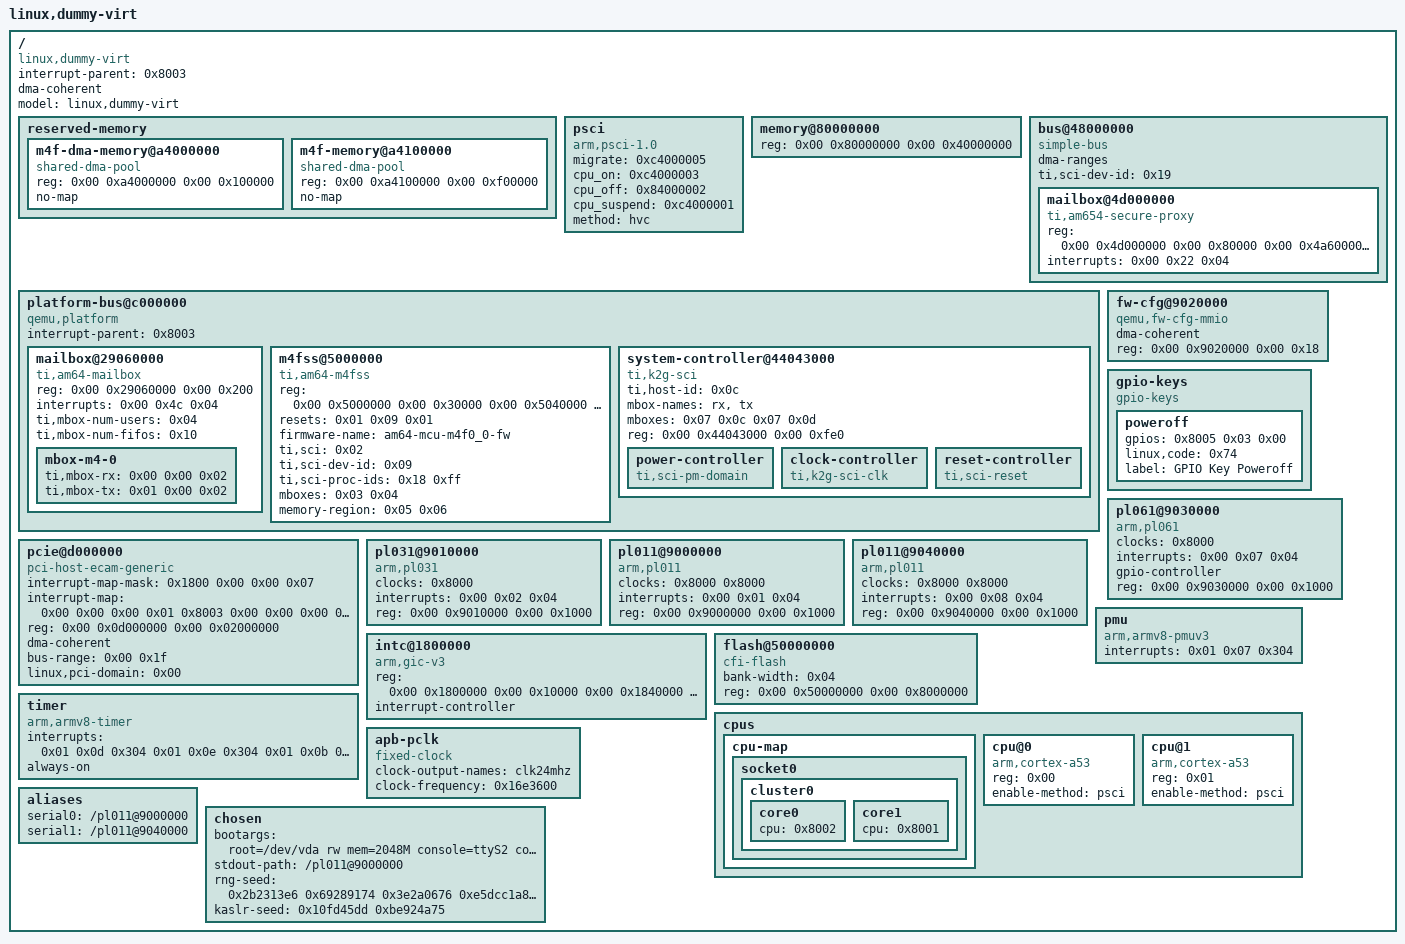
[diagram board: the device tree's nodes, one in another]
// SPDX-License-Identifier: GPL-2.0-or-later
/*
 * Copyright (c) 2026 CMBLU Energy AG
 * Author: Wadim Mueller <wafgo01@gmail.com>
 */
/dts-v1/;

/ {
	interrupt-parent = <0x8003>;
	dma-coherent;
	model = "linux,dummy-virt";
	#size-cells = <0x02>;
	#address-cells = <0x02>;
	compatible = "linux,dummy-virt";

	reserved-memory {
		#address-cells = <0x02>;
		#size-cells = <0x02>;
		ranges;

		m4f-dma-memory@a4000000 {
			compatible = "shared-dma-pool";
			reg = <0x00 0xa4000000 0x00 0x100000>;
			no-map;
			phandle = <0x05>;
		};

		m4f-memory@a4100000 {
			compatible = "shared-dma-pool";
			reg = <0x00 0xa4100000 0x00 0xf00000>;
			no-map;
			phandle = <0x06>;
		};
	};

	psci {
		migrate = <0xc4000005>;
		cpu_on = <0xc4000003>;
		cpu_off = <0x84000002>;
		cpu_suspend = <0xc4000001>;
		method = "hvc";
		compatible = "arm,psci-1.0", "arm,psci-0.2", "arm,psci";
	};

	memory@80000000 {
		reg = <0x00 0x80000000 0x00 0x40000000>;
		device_type = "memory";
	};

	bus@48000000 {
		bootph-all;
		compatible = "simple-bus";
		#address-cells = <0x02>;
		#size-cells = <0x02>;
		dma-ranges;
		ranges = <0x00 0x48000000 0x00 0x48000000 0x00 0x6400000>;
		ti,sci-dev-id = <0x19>;

		mailbox@4d000000 {
			bootph-all;
			compatible = "ti,am654-secure-proxy";
			#mbox-cells = <0x01>;
			reg-names = "target_data", "rt", "scfg";
			reg = <0x00 0x4d000000 0x00 0x80000 0x00 0x4a600000 0x00 0x80000 0x00 0x4a400000 0x00 0x80000>;
			interrupt-names = "rx_012";
			interrupts = <0x00 0x22 0x04>;
			phandle = <0x07>;
		};
	};

	platform-bus@c000000 {
		interrupt-parent = <0x8003>;
		ranges;
		#address-cells = <0x02>;
		#size-cells = <0x02>;
		compatible = "qemu,platform", "simple-bus";

		mailbox@29060000 {
			compatible = "ti,am64-mailbox";
			reg = <0x00 0x29060000 0x00 0x200>;
			interrupts = <0x00 0x4c 0x04>;
			#mbox-cells = <0x01>;
			ti,mbox-num-users = <0x04>;
			ti,mbox-num-fifos = <0x10>;
			status = "okay";
			phandle = <0x03>;

			mbox-m4-0 {
				ti,mbox-rx = <0x00 0x00 0x02>;
				ti,mbox-tx = <0x01 0x00 0x02>;
				phandle = <0x04>;
			};
		};

		m4fss@5000000 {
			compatible = "ti,am64-m4fss";
			reg = <0x00 0x5000000 0x00 0x30000 0x00 0x5040000 0x00 0x10000>;
			reg-names = "iram", "dram";
			resets = <0x01 0x09 0x01>;
			firmware-name = "am64-mcu-m4f0_0-fw";
			ti,sci = <0x02>;
			ti,sci-dev-id = <0x09>;
			ti,sci-proc-ids = <0x18 0xff>;
			mboxes = <0x03 0x04>;
			memory-region = <0x05 0x06>;
			status = "okay";
		};

		system-controller@44043000 {
			bootph-all;
			compatible = "ti,k2g-sci";
			ti,host-id = <0x0c>;
			mbox-names = "rx", "tx";
			mboxes = <0x07 0x0c 0x07 0x0d>;
			reg-names = "debug_messages";
			reg = <0x00 0x44043000 0x00 0xfe0>;
			phandle = <0x02>;

			power-controller {
				bootph-all;
				compatible = "ti,sci-pm-domain";
				#power-domain-cells = <0x02>;
			};

			clock-controller {
				bootph-all;
				compatible = "ti,k2g-sci-clk";
				#clock-cells = <0x02>;
			};

			reset-controller {
				bootph-all;
				compatible = "ti,sci-reset";
				#reset-cells = <0x02>;
				phandle = <0x01>;
			};
		};
	};

	fw-cfg@9020000 {
		dma-coherent;
		reg = <0x00 0x9020000 0x00 0x18>;
		compatible = "qemu,fw-cfg-mmio";
	};

	gpio-keys {
		compatible = "gpio-keys";

		poweroff {
			gpios = <0x8005 0x03 0x00>;
			linux,code = <0x74>;
			label = "GPIO Key Poweroff";
		};
	};

	pl061@9030000 {
		phandle = <0x8005>;
		clock-names = "apb_pclk";
		clocks = <0x8000>;
		interrupts = <0x00 0x07 0x04>;
		gpio-controller;
		#gpio-cells = <0x02>;
		compatible = "arm,pl061", "arm,primecell";
		reg = <0x00 0x9030000 0x00 0x1000>;
	};

	pcie@d000000 {
		interrupt-map-mask = <0x1800 0x00 0x00 0x07>;
		interrupt-map = <0x00 0x00 0x00 0x01 0x8003 0x00 0x00 0x00 0x03 0x04 0x00 0x00 0x00 0x02 0x8003 0x00 0x00 0x00 0x04 0x04 0x00 0x00 0x00 0x03 0x8003 0x00 0x00 0x00 0x05 0x04 0x00 0x00 0x00 0x04 0x8003 0x00 0x00 0x00 0x06 0x04 0x800 0x00 0x00 0x01 0x8003 0x00 0x00 0x00 0x04 0x04 0x800 0x00 0x00 0x02 0x8003 0x00 0x00 0x00 0x05 0x04 0x800 0x00 0x00 0x03 0x8003 0x00 0x00 0x00 0x06 0x04 0x800 0x00 0x00 0x04 0x8003 0x00 0x00 0x00 0x03 0x04 0x1000 0x00 0x00 0x01 0x8003 0x00 0x00 0x00 0x05 0x04 0x1000 0x00 0x00 0x02 0x8003 0x00 0x00 0x00 0x06 0x04 0x1000 0x00 0x00 0x03 0x8003 0x00 0x00 0x00 0x03 0x04 0x1000 0x00 0x00 0x04 0x8003 0x00 0x00 0x00 0x04 0x04 0x1800 0x00 0x00 0x01 0x8003 0x00 0x00 0x00 0x06 0x04 0x1800 0x00 0x00 0x02 0x8003 0x00 0x00 0x00 0x03 0x04 0x1800 0x00 0x00 0x03 0x8003 0x00 0x00 0x00 0x04 0x04 0x1800 0x00 0x00 0x04 0x8003 0x00 0x00 0x00 0x05 0x04>;
		#interrupt-cells = <0x01>;
		ranges = <0x1000000 0x00 0x00 0x00 0x3eff0000 0x00 0x10000 0x2000000 0x00 0x68000000 0x00 0x68000000 0x00 0x08000000>;
		reg = <0x00 0x0d000000 0x00 0x02000000>;
		dma-coherent;
		bus-range = <0x00 0x1f>;
		linux,pci-domain = <0x00>;
		#size-cells = <0x02>;
		#address-cells = <0x03>;
		device_type = "pci";
		compatible = "pci-host-ecam-generic";
	};

	pl031@9010000 {
		clock-names = "apb_pclk";
		clocks = <0x8000>;
		interrupts = <0x00 0x02 0x04>;
		reg = <0x00 0x9010000 0x00 0x1000>;
		compatible = "arm,pl031", "arm,primecell";
	};

	pl011@9000000 {
		clock-names = "uartclk", "apb_pclk";
		clocks = <0x8000 0x8000>;
		interrupts = <0x00 0x01 0x04>;
		reg = <0x00 0x9000000 0x00 0x1000>;
		compatible = "arm,pl011", "arm,primecell";
	};

	pl011@9040000 {
		clock-names = "uartclk", "apb_pclk";
		clocks = <0x8000 0x8000>;
		interrupts = <0x00 0x08 0x04>;
		reg = <0x00 0x9040000 0x00 0x1000>;
		compatible = "arm,pl011", "arm,primecell";
	};

	pmu {
		interrupts = <0x01 0x07 0x304>;
		compatible = "arm,armv8-pmuv3";
	};

	intc@1800000 {
		phandle = <0x8003>;
		reg = <0x00 0x1800000 0x00 0x10000
		       0x00 0x1840000 0x00 0x40000>;
		compatible = "arm,gic-v3";
		ranges;
		#size-cells = <0x02>;
		#address-cells = <0x02>;
		interrupt-controller;
		#interrupt-cells = <0x03>;
	};


	flash@50000000 {
		bank-width = <0x04>;
		reg = <0x00 0x50000000 0x00 0x8000000>;
		compatible = "cfi-flash";
	};
	cpus {
		#size-cells = <0x00>;
		#address-cells = <0x01>;

		cpu-map {

			socket0 {

				cluster0 {

					core0 {
						cpu = <0x8002>;
					};

					core1 {
						cpu = <0x8001>;
					};
				};
			};
		};

		cpu@0 {
			phandle = <0x8002>;
			reg = <0x00>;
			enable-method = "psci";
			compatible = "arm,cortex-a53";
			device_type = "cpu";
		};

		cpu@1 {
			phandle = <0x8001>;
			reg = <0x01>;
			enable-method = "psci";
			compatible = "arm,cortex-a53";
			device_type = "cpu";
		};
	};

	timer {
		interrupts = <0x01 0x0d 0x304 0x01 0x0e 0x304 0x01 0x0b 0x304 0x01 0x0a 0x304>;
		always-on;
		compatible = "arm,armv8-timer", "arm,armv7-timer";
	};

	apb-pclk {
		phandle = <0x8000>;
		clock-output-names = "clk24mhz";
		clock-frequency = <0x16e3600>;
		#clock-cells = <0x00>;
		compatible = "fixed-clock";
	};

	aliases {
		serial0 = "/pl011@9000000";
		serial1 = "/pl011@9040000";
	};

	chosen {
		bootargs = "root=/dev/vda rw  mem=2048M console=ttyS2 console=ttyAMA0 swiotlb=0 audit=0";
		stdout-path = "/pl011@9000000";
		rng-seed = <0x2b2313e6 0x69289174 0x3e2a0676 0xe5dcc1a8 0xc1e04c16 0x988a8076 0x6e26a8c8 0x2a273f53>;
		kaslr-seed = <0x10fd45dd 0xbe924a75>;
	};
};
